# WKUP_j7aen_wkup_ctrl_mmr0_CFG0 register map
Vendor: Texas Instruments
Registers are 32-bit, read-write, reset 0x0 unless marked. A register's access mark holds for its fields unless they carry their own. Offsets are as the file gives them; [hi:lo] are bit positions; {n}, {i} and the like mark numbered series.

## WKUP_j7aen_wkup_ctrl_mmr0_CFG0 (part 3 of 3)
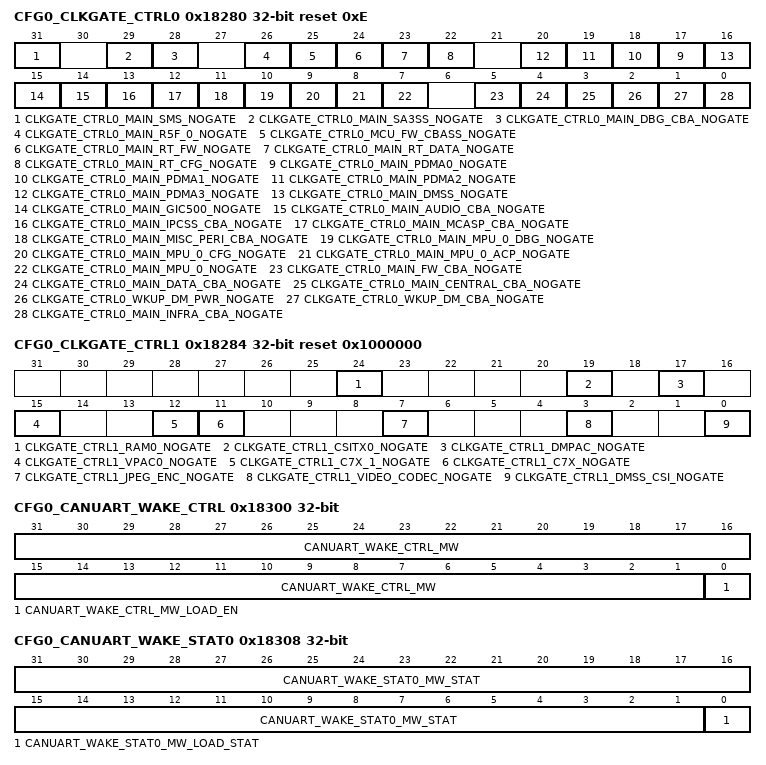
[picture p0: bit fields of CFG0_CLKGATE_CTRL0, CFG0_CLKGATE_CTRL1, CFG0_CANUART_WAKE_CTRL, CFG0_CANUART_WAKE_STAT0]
0x18280 CFG0_CLKGATE_CTRL0 reset 0xE
  [31] CLKGATE_CTRL0_MAIN_SMS_NOGATE — MAIN domain SMS auto clock gate on idle deactivate. Field values (others are reserved): 1'b0 - ACTIVE 1'b1 - INACTIVE
  [29] CLKGATE_CTRL0_MAIN_SA3SS_NOGATE — MAIN domain SA3SS auto clock gate on idle deactivate. Field values (others are reserved): 1'b0 - ACTIVE 1'b1 - INACTIVE
  [28] CLKGATE_CTRL0_MAIN_DBG_CBA_NOGATE — MAIN domain Debug CBASS auto clock gate on idle deactivate. Field values (others are reserved): 1'b0 - ACTIVE 1'b1 - INACTIVE
  [26] CLKGATE_CTRL0_MAIN_R5F_0_NOGATE — MAIN domain R5FSS auto clock gate on idle deactivate Field values (others are reserved): 1'b0 - ACTIVE 1'b1 - INACTIVE
  [25] CLKGATE_CTRL0_MCU_FW_CBASS_NOGATE — MCU domain FW CBASS auto clock gate on idle deactivate Field values (others are reserved): 1'b0 - ACTIVE 1'b1 - INACTIVE
  [24] CLKGATE_CTRL0_MAIN_RT_FW_NOGATE — MAIN domain RT FW CBASS auto clock gate on idle deactivate Field values (others are reserved): 1'b0 - ACTIVE 1'b1 - INACTIVE
  [23] CLKGATE_CTRL0_MAIN_RT_DATA_NOGATE — MAIN domain RT DATA CBASS auto clock gate on idle deactivate Field values (others are reserved): 1'b0 - ACTIVE 1'b1 - INACTIVE
  [22] CLKGATE_CTRL0_MAIN_RT_CFG_NOGATE — MAIN domain RT CFG CBASS auto clock gate on idle deactivate Field values (others are reserved): 1'b0 - ACTIVE 1'b1 - INACTIVE
  [n+17] CLKGATE_CTRL0_MAIN_PDMA{n}_NOGATE (n=0..3) — MAIN domain PDMA{n} auto clock gate on idle deactivate. Field values (others are reserved): 1'b0 - ACTIVE 1'b1 - INACTIVE
  [16] CLKGATE_CTRL0_MAIN_DMSS_NOGATE — MAIN domain DMSS auto clock gate on idle deactivate. Field values (others are reserved): 1'b0 - ACTIVE 1'b1 - INACTIVE
  [15] CLKGATE_CTRL0_MAIN_GIC500_NOGATE — MAIN MPUSS0 GIC500 auto clock gate on idle deactivate. Field values (others are reserved): 1'b0 - ACTIVE 1'b1 - INACTIVE
  [14] CLKGATE_CTRL0_MAIN_AUDIO_CBA_NOGATE — MAIN domain Infrastructure bus (AUDIO) auto clock gate on idle deactivate. Field values (others are reserved): 1'b0 - ACTIVE 1'b1 - INACTIVE
  [13] CLKGATE_CTRL0_MAIN_IPCSS_CBA_NOGATE — MAIN domain Infrastructure CBASS auto clock gate on idle deactivate. Field values (others are reserved): 1'b0 - ACTIVE 1'b1 - INACTIVE
  [12] CLKGATE_CTRL0_MAIN_MCASP_CBA_NOGATE — MAIN domain Infrastructure bus (McASP) auto clock gate on idle deactivate. Field values (others are reserved): 1'b0 - ACTIVE 1'b1 - INACTIVE
  [11] CLKGATE_CTRL0_MAIN_MISC_PERI_CBA_NOGATE — MAIN domain Infrastructure bus (Misc Peripehal) auto clock gate on idle deactivate. Field values (others are reserved): 1'b0 - ACTIVE 1'b1 - INACTIVE
  [10] CLKGATE_CTRL0_MAIN_MPU_0_DBG_NOGATE — MAIN MPUSS0 Debug Port auto clock gate on idle deactivate. Field values (others are reserved): 1'b0 - ACTIVE 1'b1 - INACTIVE
  [9] CLKGATE_CTRL0_MAIN_MPU_0_CFG_NOGATE — MAIN MPUSS0 Configuration Port auto clock gate on idle deactivate. Field values (others are reserved): 1'b0 - ACTIVE 1'b1 - INACTIVE
  [8] CLKGATE_CTRL0_MAIN_MPU_0_ACP_NOGATE — MAIN MPUSS0 ACP auto clock gate on idle deactivate. Field values (others are reserved): 1'b0 - ACTIVE 1'b1 - INACTIVE
  [7] CLKGATE_CTRL0_MAIN_MPU_0_NOGATE — MAIN MPUSS0 auto clock gate on idle deactivate. Field values (others are reserved): 1'b0 - ACTIVE 1'b1 - INACTIVE
  [5] CLKGATE_CTRL0_MAIN_FW_CBA_NOGATE — MAIN domain data bus auto clock gate on idle deactivate. Field values (others are reserved): 1'b0 - ACTIVE 1'b1 - INACTIVE
  [4] CLKGATE_CTRL0_MAIN_DATA_CBA_NOGATE — MAIN domain data bus auto clock gate on idle deactivate. Field values (others are reserved): 1'b0 - ACTIVE 1'b1 - INACTIVE
  [3] CLKGATE_CTRL0_MAIN_CENTRAL_CBA_NOGATE — WKUP domain Infrastructure ECC aggregator auto clock gate on idle deactivate. Field values (others are reserved): 1'b0 - ACTIVE 1'b1 - INACTIVE
  [2] CLKGATE_CTRL0_WKUP_DM_PWR_NOGATE — WKUP domain Device Manager auto clock gate on idle deactivate. Field values (others are reserved): 1'b0 - ACTIVE 1'b1 - INACTIVE
  [1] CLKGATE_CTRL0_WKUP_DM_CBA_NOGATE — WKUP domain device manager CBA auto clock gate on idle deactivate. Field values (others are reserved): 1'b0 - ACTIVE 1'b1 - INACTIVE
  [0] CLKGATE_CTRL0_MAIN_INFRA_CBA_NOGATE — MAIN domain Infrastructure bus auto clock gate on idle deactivate. Field values (others are reserved): 1'b0 - ACTIVE 1'b1 - INACTIVE
0x18284 CFG0_CLKGATE_CTRL1 reset 0x1000000
  [24] CLKGATE_CTRL1_RAM0_NOGATE — MAIN SRAM auto clockgate on idle deactivate Field values (others are reserved): 1'b0 - ACTIVE 1'b1 - INACTIVE
  [19] CLKGATE_CTRL1_CSITX0_NOGATE — CSI-TX0 auto clock gate on idle deactivate. Field values (others are reserved): 1'b0 - ACTIVE 1'b1 - INACTIVE
  [17] CLKGATE_CTRL1_DMPAC_NOGATE — DMPAC auto clock gate on idle deactivate. Field values (others are reserved): 1'b0 - ACTIVE 1'b1 - INACTIVE
  [15] CLKGATE_CTRL1_VPAC0_NOGATE — VPAC0 auto clock gate on idle deactivate. Field values (others are reserved): 1'b0 - ACTIVE 1'b1 - INACTIVE
  [12] CLKGATE_CTRL1_C7X_1_NOGATE — C7x_1 auto clock gate on idle deactivate. Field values (others are reserved): 1'b0 - ACTIVE 1'b1 - INACTIVE
  [11] CLKGATE_CTRL1_C7X_NOGATE — C7x auto clock gate on idle deactivate. Field values (others are reserved): 1'b0 - ACTIVE 1'b1 - INACTIVE
  [7] CLKGATE_CTRL1_JPEG_ENC_NOGATE — JPEG Encoder auto clock gate on idle deactivate. Field values (others are reserved): 1'b0 - ACTIVE 1'b1 - INACTIVE
  [3] CLKGATE_CTRL1_VIDEO_CODEC_NOGATE — VIDEO CODEC auto clock gate on idle deactivate. Field values (others are reserved): 1'b0 - ACTIVE 1'b1 - INACTIVE
  [0] CLKGATE_CTRL1_DMSS_CSI_NOGATE — DMSS_CSI auto clock gate on idle deactivate. Field values (others are reserved): 1'b0 - ACTIVE 1'b1 - INACTIVE
0x18300 CFG0_CANUART_WAKE_CTRL
  [31:1] CANUART_WAKE_CTRL_MW — CANUART IO magic word. The lower 23 bits determine if the device enters CANUART IO isolation when mw_load_en is set. If the lower 23 bits match the ACTIVATE value (0x5AAAAA), then CANUART IO Isolation is entered, any other value will prevent entry. The upper 8 bits of this register are software defined and do not determine whether or not CANUART IO isolation is entered. Field values (others are reserved): 31'h005AAAAA - ACTIVATE 31'h00000000 - DEACTIVATE
  [0] CANUART_WAKE_CTRL_MW_LOAD_EN — Magic word load activate Setting this bit loads and locks the mw field for CANUART IO isolation. If the mw field matches ACTIVATE, CANUART IO Isolation is initiated. Field values (others are reserved): 1'b0 - UNLOCK 1'b1 - LOCK_AND_LOAD
0x18308 CFG0_CANUART_WAKE_STAT0 ro
  [31:1] CANUART_WAKE_STAT0_MW_STAT — CANUART magic word status Indicates the latched value of the mw field.
  [0] CANUART_WAKE_STAT0_MW_LOAD_STAT — Magic word load status. Indicates the latched value of the mw_load_en bit
0x1830C CFG0_CANUART_WAKE_STAT1 ro
  [0] CANUART_WAKE_STAT1_CANUART_IO_MODE — Indicates if CANUART IO wakeup mode is activated. Field values (others are reserved): 1'b0 - INACTIVE 1'b1 - ACTIVATED
0x18310 CFG0_CANUART_WAKE_OFF_MODE
  [31:0] CANUART_WAKE_OFF_MODE_MW — magic word
0x18318 CFG0_CANUART_WAKE_OFF_MODE_STAT ro
  [31:0] CANUART_WAKE_OFF_MODE_STAT_MW — returned magic word
0x18320 CFG0_CANUART_WAKE_RESUME_KEY
  [31:0] KEYVAL — key value
0x18340 CFG0_CANUART_WAKE_RESUME_KEY_STAT ro
  [31:0] KEYVAL — returned key value
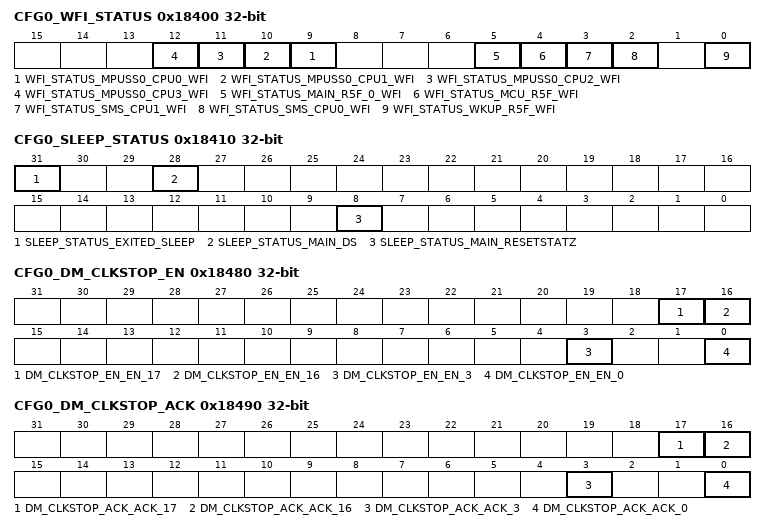
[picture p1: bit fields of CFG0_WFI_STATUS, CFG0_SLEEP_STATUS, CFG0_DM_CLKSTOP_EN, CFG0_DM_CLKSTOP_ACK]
0x18400 CFG0_WFI_STATUS ro
  [n+9] WFI_STATUS_MPUSS0_CPU{n}_WFI (n=0..3) — WFI status of MPUSS0 CPU{n} (only valid when CPU is out of reset) Field values (others are reserved): 1'b0 - UNKNOWN 1'b1 - WFI_ACTIVE
  [5] WFI_STATUS_MAIN_R5F_0_WFI — WFI status of MAIN Cortex R5F (only valid when CPU is out of reset) Field values (others are reserved): 1'b0 - UNKNOWN 1'b1 - WFI_ACTIVE
  [4] WFI_STATUS_MCU_R5F_WFI — WFI status of MCU Cortex R5F (only valid when CPU is out of reset) Field values (others are reserved): 1'b0 - UNKNOWN 1'b1 - WFI_ACTIVE
  [3] WFI_STATUS_SMS_CPU1_WFI — WFI status of SMS Cortex M4F1 (only valid when CPU is out of reset) Field values (others are reserved): 1'b0 - UNKNOWN 1'b1 - WFI_ACTIVE
  [2] WFI_STATUS_SMS_CPU0_WFI — WFI status of SMS Cortex M4F0 (only valid when CPU is out of reset) Field values (others are reserved): 1'b0 - UNKNOWN 1'b1 - WFI_ACTIVE
  [0] WFI_STATUS_WKUP_R5F_WFI — WFI status of Device Manager Cortex R5F (only valid when CPU is out of reset) Field values (others are reserved): 1'b0 - UNKNOWN 1'b1 - WFI_ACTIVE
0x18410 CFG0_SLEEP_STATUS access not given
  [31] SLEEP_STATUS_EXITED_SLEEP — Captures disable/gating of HFOSC. Allows DM to confirm, after the WFI instruction, to determine whether or not HFOSC clocks were actually gated (a pending event may cancel the sleep sequence early). Field values (others are reserved): 1'b0 - OTHER 1'b1 - SLEEP_EXIT (access R/W1TC)
  [28] SLEEP_STATUS_MAIN_DS — Captures DS_MAIN por_pdoff assertion, so that after deepsleep exit software can differentiate between a regular power on reset and a main power on reset due to deepsleep exit. Write 1 to Clear this bit. Field values (others are reserved): 1'b0 - OTHER 1'b1 - DS_EXIT (access R/W1TC)
  [8] SLEEP_STATUS_MAIN_RESETSTATZ ro — Reflects the status of the main domain reset (active low) Field values (others are reserved): 1'b0 - ASSERTED 1'b1 - DEASSERTED
0x18418 CFG0_DS_MAGIC_WORD
  [31:0] DS_MAGIC_WORD_DS_MAGIC_WORD — Magic Word Indicating State of Deep Sleep
0x18420 CFG0_DS_MAIN reset 0xF
  [3:0] DS_MAIN_POR_PDOFF — Signal Puts main SMS, DebugSS and MainIP Power Domains into Power Off state, and asserts Main Power On Reset. Field values (others are reserved): 4'b0110 - Off 4'b1111 - On
0x18440 CFG0_DS_DM_RESET reset 0xF
  [3:0] DS_DM_RESET_MASK — Signal used to mask main domain resets from Device Manager / Wakeup and MCU Ips Field values (others are reserved): 4'b0110 - Masked 4'b1111 - UnMasked
0x18460 CFG0_DS_USB0_RESET reset 0xF
  [3:0] DS_USB0_RESET_MASK — Signal used to block reset to the USBSS0 Field values (others are reserved): 4'b0110 - Masked 4'b1111 - UnMasked
0x18464 CFG0_DS_USB1_RESET reset 0xF
  [3:0] DS_USB1_RESET_MASK — Signal used to block reset to the USBSS1 Field values (others are reserved): 4'b0110 - Masked 4'b1111 - UnMasked
0x18480 CFG0_DM_CLKSTOP_EN
  [17] DM_CLKSTOP_EN_EN_17 — WKUP DMTIMER1 Participation in Clockstop Req Group Field values (others are reserved): 1'b0 - NOT_PARTICIPATING 1'b1 - PARTICIPATING
  [16] DM_CLKSTOP_EN_EN_16 — WKUP DMTIMER0 Participation in Clockstop Req Group Field values (others are reserved): 1'b0 - NOT_PARTICIPATING 1'b1 - PARTICIPATING
  [3] DM_CLKSTOP_EN_EN_3 — WKUP UART0 Participation in Clockstop Req Group Field values (others are reserved): 1'b0 - NOT_PARTICIPATING 1'b1 - PARTICIPATING
  [0] DM_CLKSTOP_EN_EN_0 — WKUP I2C0 Participation in Clockstop Req Group Field values (others are reserved): 1'b0 - NOT_PARTICIPATING 1'b1 - PARTICIPATING
0x18490 CFG0_DM_CLKSTOP_ACK ro
  [17] DM_CLKSTOP_ACK_ACK_17 — WKUP DMTIMER1 Clockstop Ack Status Field values (others are reserved): 1'b0 - NACK 1'b1 - ACK
  [16] DM_CLKSTOP_ACK_ACK_16 — WKUP DMTIMER0 Clockstop Ack Status Field values (others are reserved): 1'b0 - NACK 1'b1 - ACK
  [3] DM_CLKSTOP_ACK_ACK_3 — WKUP UART0 Clockstop Ack Status Field values (others are reserved): 1'b0 - NACK 1'b1 - ACK
  [0] DM_CLKSTOP_ACK_ACK_0 — WKUP I2C0 Clockstop Ack Status Field values (others are reserved): 1'b0 - NACK 1'b1 - ACK
0x184A0 CFG0_DM_GRP_CLKSTOP_REQ
  [0] DM_GRP_CLKSTOP_REQ_REQ — Controls Assertion of Clockstop Request to IPs participating in Clockstop Req Group Field values (others are reserved): 1'b0 - DEASSERT_REQ 1'b1 - ASSERT_REQ
0x184A4 CFG0_DM_GRP_CLKSTOP_ACK ro
  [0] DM_GRP_CLKSTOP_ACK_ACK — Status of IPs Participating in Clockstop Ack Group. If DM_CLKSTOP_EN is 0 (no IPs participating) this bit always reads 1. If one or more participating peripherals is returning NACK, this bit reads PENDING. Field values (others are reserved): 1'b0 - PENDING 1'b1 - ALL_ACK
0x18500 CFG0_DEVICE_TYPE ro
  [7:4] DEVICE_TYPE_SMS_DEV_TYPE — Type of device reported by SMS. Values not listed should be interpreted as BAD. Field values (others are reserved): 4b0101 - DT_TEST 4b1001 - DT_EMU 4b1010 - DT_HS 4b0011 - DT_GP
{0x19100+4i} CFG0_CLAIMREG_P6_R{i}_READONLY ro (i=0..10)
  [31:0] CLAIMREG_P6_R{i}_READONLY — Claim bits for Partition 6
0x1A040 CFG0_FW_CTRL_OUT0_PROXY
  [31:0] FW_CTRL_OUT0_FW_CTRL_OUT0_PROXY — Unused
0x1A044 CFG0_FW_CTRL_OUT0_SET_PROXY access not given reset not defined
0x1A048 CFG0_FW_CTRL_OUT0_CLR_PROXY access not given reset not defined
0x1A04C CFG0_FW_STS_IN0_PROXY access not given reset not defined
0x1A050 CFG0_FW_CTRL_OUT1_PROXY access not given reset not defined
0x1A054 CFG0_FW_CTRL_OUT1_SET_PROXY access not given reset not defined
0x1A058 CFG0_FW_CTRL_OUT1_CLR_PROXY access not given reset not defined
0x1A05C CFG0_FW_STS_IN1_PROXY access not given reset not defined
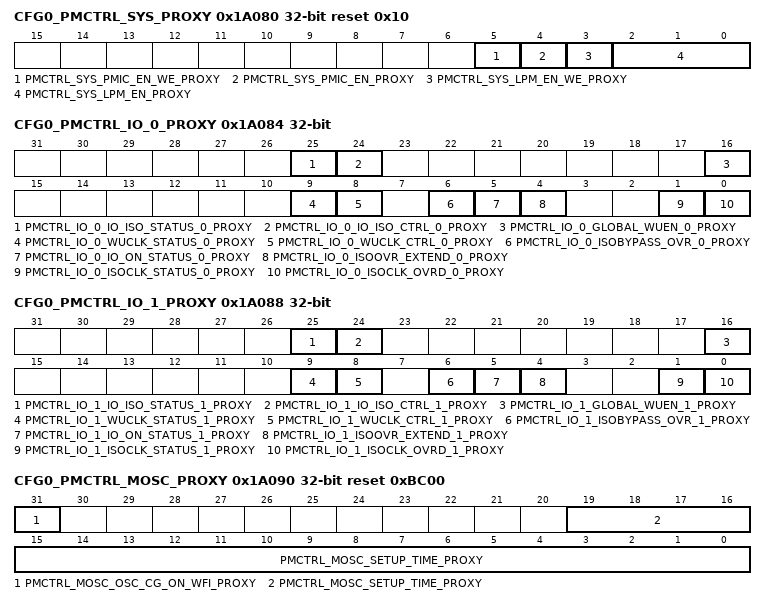
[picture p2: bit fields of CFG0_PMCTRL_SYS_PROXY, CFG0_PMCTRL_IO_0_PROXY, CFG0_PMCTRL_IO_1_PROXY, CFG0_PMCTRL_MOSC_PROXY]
0x1A080 CFG0_PMCTRL_SYS_PROXY reset 0x10
  [5] PMCTRL_SYS_PMIC_EN_WE_PROXY — Unused Field - Value is Don't Care
  [4] PMCTRL_SYS_PMIC_EN_PROXY — Controls state of PMIC_LPM_EN_OUT when LPM_EN[2:0] is 000
  [3] PMCTRL_SYS_LPM_EN_WE_PROXY — Unused Field - Value is Don't Care
  [2:0] PMCTRL_SYS_LPM_EN_PROXY — Controls whether PMIC_LPM_EN_OUT is driven by the pmic_en bit, or by deep sleep logic. Field values (others are reserved): 3'b000 - PMIC_LPM_EN_OUT controlled by pmic_en bit. 3'b101 - PMIC_LPM_EN_OUT controlled by DeepSleep Logic
0x1A084 CFG0_PMCTRL_IO_0_PROXY access per field
  [25] PMCTRL_IO_0_IO_ISO_STATUS_0_PROXY ro — IO ISO Status. Read 0: IO isolation not active. Read 1: IO isolation active. Reflects value of DM input port io_isoack coming back from IO pad ring.
  [24] PMCTRL_IO_0_IO_ISO_CTRL_0_PROXY rw — IO ISO control. Writing this bit to 1 will kick off IO isolation.
  [16] PMCTRL_IO_0_GLOBAL_WUEN_0_PROXY rw — Global IO wakeup activate. This is a gating condition to all individual IO WUEN coming from control module. Gating is done in the Spinner logic. 0:All individual IO WUEN are gated in the Spinner logic (override to 0). 1: All individual IO WUEN from control module are going to Ios. Map to DM input port io_globalwkupen
  [9] PMCTRL_IO_0_WUCLK_STATUS_0_PROXY ro — Reflects value of DM input port io_wuclkack coming back from IO pad ring.
  [8] PMCTRL_IO_0_WUCLK_CTRL_0_PROXY rw — Direct control on WUCLKIN signal to IO pad ring.0:WUCLKIN signal is driven to 0.IO wakeup daisy chain is functional as well as IO whose wakeup feature is activated. 1:WUCLKIN signal is driven to 1. IO wakeup daisy chain is reset and is latching current pad states and WUEN inputs.
  [6] PMCTRL_IO_0_ISOBYPASS_OVR_0_PROXY rw — This MMR bit drives directly DM output port io_isobypassundefined.
  [5] PMCTRL_IO_0_IO_ON_STATUS_0_PROXY ro — Gives the functional status of the IO ring. Read 0: Part or all of the Ios are not in the ON state that is are in isolation state. Read 1: All Ios are in the ON state. io_on_status = assign 1 if (io_iso == 0 & io_isoack==0 & io_iso_clk == 0 & io_isoclk_ack = 0 ) else 0;
  [4] PMCTRL_IO_0_ISOOVR_EXTEND_0_PROXY rw — This drives the SOC chain ISO-OVERRIDE global control. This bit drives directly the DM output port io_isoovrundefined. At the SOC level it is used to activate when 1 or gate-off when 0, the individual ISOOR for each IO. This operates as a global activate/disable for the individual IOs.Control for IO isolation extension. '0' IO isolation is not extended. Transition happens as soon as automatic restore is completed. '1' IO isolation is extended. The IOs whose ISOOVR bits have been individually set in their PADCFG MMRs will all get its IO isolation extended beyond the point when the initial IO daisy chain isolation is released.
  [1] PMCTRL_IO_0_ISOCLK_STATUS_0_PROXY ro — Reflects value of DM input port io_isoclkack coming back from IO pad ring.
  [0] PMCTRL_IO_0_ISOCLK_OVRD_0_PROXY rw — Override control on ISOCLKIN signal to IO pad ring. When not overridden this signal is controlled by hardware only. 0 ISOCLKIN signal is not override. 1 ISOCLKIN signal is overridden to active value ('1').
0x1A088 CFG0_PMCTRL_IO_1_PROXY access per field
  [25] PMCTRL_IO_1_IO_ISO_STATUS_1_PROXY ro — IO ISO Status. Read 0: IO isolation not active. Read 1: IO isolation active. Reflects value of DM input port io_isoack coming back from IO pad ring.
  [24] PMCTRL_IO_1_IO_ISO_CTRL_1_PROXY rw — IO ISO control. Writing this bit to 1 will kick off IO isolation.
  [16] PMCTRL_IO_1_GLOBAL_WUEN_1_PROXY rw — Global IO wakeup activate. This is a gating condition to all individual IO WUEN coming from control module. Gating is done in the Spinner logic. 0:All individual IO WUEN are gated in the Spinner logic (override to 0). 1: All individual IO WUEN from control module are going to Ios. Map to DM input port io_globalwkupen
  [9] PMCTRL_IO_1_WUCLK_STATUS_1_PROXY ro — Reflects value of DM input port io_wuclkack coming back from IO pad ring.
  [8] PMCTRL_IO_1_WUCLK_CTRL_1_PROXY rw — Direct control on WUCLKIN signal to IO pad ring.0:WUCLKIN signal is driven to 0.IO wakeup daisy chain is functional as well as IO whose wakeup feature is activated. 1:WUCLKIN signal is driven to 1. IO wakeup daisy chain is reset and is latching current pad states and WUEN inputs.
  [6] PMCTRL_IO_1_ISOBYPASS_OVR_1_PROXY rw — This MMR bit drives directly DM output port io_isobypassundefined.
  [5] PMCTRL_IO_1_IO_ON_STATUS_1_PROXY ro — Gives the functional status of the IO ring. Read 0: Part or all of the Ios are not in the ON state that is are in isolation state. Read 1: All Ios are in the ON state. io_on_status = assign 1 if (io_iso == 0 & io_isoack==0 & io_iso_clk == 0 & io_isoclk_ack = 0 ) else 0;
  [4] PMCTRL_IO_1_ISOOVR_EXTEND_1_PROXY rw — This drives the SOC chain ISO-OVERRIDE global control. This bit drives directly the DM output port io_isoovrundefined. At the SOC level it is used to activate when 1 or gate-off when 0, the individual ISOOR for each IO. This operates as a global activate/disable for the individual IOs.Control for IO isolation extension. '0' IO isolation is not extended. Transition happens as soon as automatic restore is completed. '1' IO isolation is extended. The IOs whose ISOOVR bits have been individually set in their PADCFG MMRs will all get its IO isolation extended beyond the point when the initial IO daisy chain isolation is released.
  [1] PMCTRL_IO_1_ISOCLK_STATUS_1_PROXY ro — Reflects value of DM input port io_isoclkack coming back from IO pad ring.
  [0] PMCTRL_IO_1_ISOCLK_OVRD_1_PROXY rw — Override control on ISOCLKIN signal to IO pad ring. When not overridden this signal is controlled by hardware only. 0 ISOCLKIN signal is not override. 1 ISOCLKIN signal is overridden to active value ('1').
0x1A090 CFG0_PMCTRL_MOSC_PROXY reset 0xBC00
  [31] PMCTRL_MOSC_OSC_CG_ON_WFI_PROXY — To clock gate the main HFOSC, DM sets this bit then enters the WFI state at which time the HFOSC will be gated. Field values (others are reserved): 1'b0 - INACTIVE 1'b1 - ACTIVE
  [19:0] PMCTRL_MOSC_SETUP_TIME_PROXY — Number of HFOSC clock cycles before HFOSC clock is ungated to the SOC (allows the HFOSC time to stabilize after starting up, before the SOC is clocked).
0x1A098 CFG0_PM_MISC_STATUS_PROXY ro
  [1:0] PM_MISC_STATUS_OSC_CG_STAT_PROXY — HFOSC Clock Gating State Field values (others are reserved): 2'b00 - HFOSC_OFF 2'b01 - HFOSC_OFF2ON (transition state) 2'b10 - HFOSC_ON2OFF (transition state) 2'b11 - HFOSC_ON
0x1A09C CFG0_PMCTRL_IO_GLB_PROXY
  [1:0] PMCTRL_IO_GLB_DSEN_QUALIFIED_PROXY — Bit 0 puts WKUP Domain IOs in Deepsleep. Bit 1 Puts Main Domain IOs in Deepsleep. Field values (others are reserved): 2'b00 - IO_ACTIVE_ALL 2'b01 - IO_DEEPSLEEP_WKUP 2'b10 - IO_DEEPSLEEP_MAIN 2'b11 - IO_DEEPSLEEP_MAIN_AND_WKUP
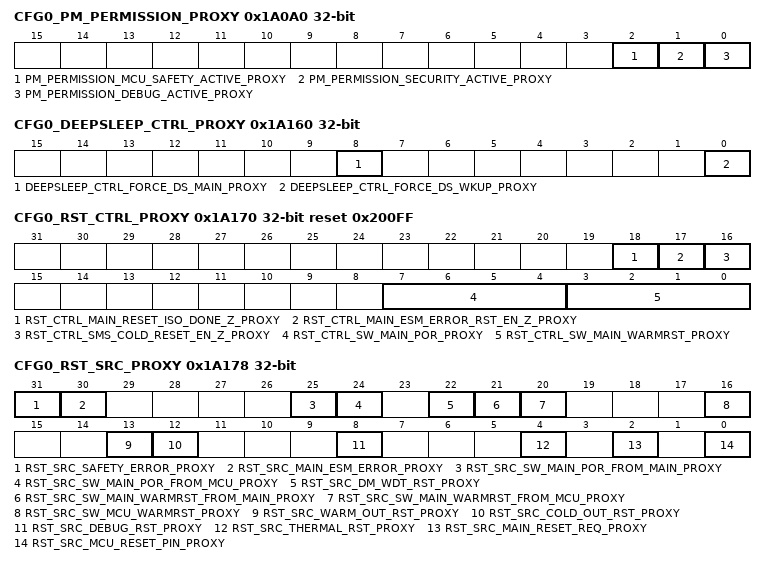
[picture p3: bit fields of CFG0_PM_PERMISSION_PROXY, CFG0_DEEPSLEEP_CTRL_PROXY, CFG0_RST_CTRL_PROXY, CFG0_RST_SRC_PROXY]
0x1A0A0 CFG0_PM_PERMISSION_PROXY ro
  [2] PM_PERMISSION_MCU_SAFETY_ACTIVE_PROXY — Read Only - Reads return a 1 when MCU RST_MAGIC_WORD is non-zero. When 1, indicates that the MCU is blocking reset and also deep sleep entry. Field values (others are reserved): 1'b0 - DS_ALLOW 1'b1 - DS_BLOCK
  [1] PM_PERMISSION_SECURITY_ACTIVE_PROXY — Read Only - Reads return the value of SMS security active. When 1, indicates that SMS is blocking deep sleep entry. Field values (others are reserved): 1'b0 - DS_ALLOW 1'b1 - DS_BLOCK
  [0] PM_PERMISSION_DEBUG_ACTIVE_PROXY — Read Only - Returns a 1 when Debug is blocking deep sleep entry. Field values (others are reserved): 1'b0 - DS_ALLOW 1'b1 - DS_BLOCK
0x1A160 CFG0_DEEPSLEEP_CTRL_PROXY
  [8] DEEPSLEEP_CTRL_FORCE_DS_MAIN_PROXY — Force all MAIN IOs into deepsleep mode when set Field values (others are reserved): 1'b0 - IO_ACTIVE 1'b1 - IO_DEEPSLEEP
  [0] DEEPSLEEP_CTRL_FORCE_DS_WKUP_PROXY — Force all WKUP IOs into deepsleep mode when set Field values (others are reserved): 1'b0 - IO_ACTIVE 1'b1 - IO_DEEPSLEEP
0x1A170 CFG0_RST_CTRL_PROXY reset 0x200FF
  [18] RST_CTRL_MAIN_RESET_ISO_DONE_Z_PROXY — Blocks Main Domain Warm Reset. Field values (others are reserved): 1'b0 - PROPOGATE 1'b1 - BLOCK
  [17] RST_CTRL_MAIN_ESM_ERROR_RST_EN_Z_PROXY — Block Reset of Main by ESM Field values (others are reserved): 1'b0 - PROPOGATE 1'b1 - BLOCK
  [16] RST_CTRL_SMS_COLD_RESET_EN_Z_PROXY — Block Reset of Main by SMS Field values (others are reserved): 1'b0 - PROPOGATE 1'b1 - BLOCK
  [7:4] RST_CTRL_SW_MAIN_POR_PROXY — Causes MAIN Domain Power On Reset. This is a fault tolerant bitfield. Automatically resets to 4'b1111 after write. Field values (others are reserved): 4'b0110 - FORCE_RESET 4'b1111 - INACTIVE
  [3:0] RST_CTRL_SW_MAIN_WARMRST_PROXY — Causes MAIN Domain Warm Reset. This is a fault tolerant bitfield. Automatically resets to 4'b1111 after write. Field values (others are reserved): 4'b0110 - FORCE_RESET 4'b1111 - INACTIVE
0x1A174 CFG0_RST_STAT_PROXY ro
  [0] RST_STAT_MCU_RESET_ISO_DONE_Z_PROXY — Indicates MCU Domain is in Reset Isolation When Active (Low) Field values (others are reserved): 1'b0 - ISOLATION 1'b1 - PASS_THROUGH
0x1A178 CFG0_RST_SRC_PROXY ro
  [31] RST_SRC_SAFETY_ERROR_PROXY — Reset Caused by MCU ESM Error. Field values (others are reserved): 1'b0 - UNKNOWN 1'b1 - DETECTED
  [30] RST_SRC_MAIN_ESM_ERROR_PROXY — Reset Caused by Main ESM Error. Field values (others are reserved): 1'b0 - UNKNOWN 1'b1 - DETECTED
  [25] RST_SRC_SW_MAIN_POR_FROM_MAIN_PROXY — Software Main Power On Reset From CTRL_MMR0. Field values (others are reserved): 1'b0 - UNKNOWN 1'b1 - DETECTED
  [24] RST_SRC_SW_MAIN_POR_FROM_MCU_PROXY — Software Main Power On Reset From MCU_CTRL_MMR0. Field values (others are reserved): 1'b0 - UNKNOWN 1'b1 - DETECTED
  [22] RST_SRC_DM_WDT_RST_PROXY — Watchdog Initiated Reset. Field values (others are reserved): 1'b0 - UNKNOWN 1'b1 - DETECTED
  [21] RST_SRC_SW_MAIN_WARMRST_FROM_MAIN_PROXY — Software Main Warm Reset From CTRL_MMR0. Field values (others are reserved): 1'b0 - UNKNOWN 1'b1 - DETECTED
  [20] RST_SRC_SW_MAIN_WARMRST_FROM_MCU_PROXY — Software Main Warm Reset From MCU_CTRL_MMR0. Field values (others are reserved): 1'b0 - UNKNOWN 1'b1 - DETECTED
  [16] RST_SRC_SW_MCU_WARMRST_PROXY — Software Warm Reset. Field values (others are reserved): 1'b0 - UNKNOWN 1'b1 - DETECTED
  [13] RST_SRC_WARM_OUT_RST_PROXY — SMS Warm Reset. Field values (others are reserved): 1'b0 - UNKNOWN 1'b1 - DETECTED
  [12] RST_SRC_COLD_OUT_RST_PROXY — SMS Cold Reset. Field values (others are reserved): 1'b0 - UNKNOWN 1'b1 - DETECTED
  [8] RST_SRC_DEBUG_RST_PROXY — Debug Subsystem Initiated Reset. Field values (others are reserved): 1'b0 - UNKNOWN 1'b1 - DETECTED
  [4] RST_SRC_THERMAL_RST_PROXY — Thermal Reset. Field values (others are reserved): 1'b0 - UNKNOWN 1'b1 - DETECTED
  [2] RST_SRC_MAIN_RESET_REQ_PROXY — Main Reset Pin. Field values (others are reserved): 1'b0 - UNKNOWN 1'b1 - DETECTED
  [0] RST_SRC_MCU_RESET_PIN_PROXY — Rest Caused by MCU Reset Pin. Field values (others are reserved): 1'b0 - UNKNOWN 1'b1 - DETECTED
0x1A17C CFG0_RST_MAGIC_WORD_PROXY ro
  [31:0] RST_MAGIC_WORD_MCU_MAGIC_WORD_PROXY — Magic Word Indicating Status of MCU Subsystem Boot
0x1A180 CFG0_WKUP0_EN_PROXY
  [31:0] WKUP0_EN_WKUPEN_PROXY — Activates Wakeup from on-chip sources. In addition to values listed, any OR combination of the values is also valid. Field values (others are reserved): 32'h00000001 - WKUP_I2C0 32'h00000002 - WKUP_USART0 32'h00000004 - MCU_GPIO0 32'h00000008 - DEBUG undefined - undefined 32'h00000020 - WKUP_TIMER0 32'h00000040 - WKUP_TIMER1 32'h00000080 - WKUP_RTC 32'h00000100 - MAIN_RESET_REQz 32'h00000200 - USB0_IN_BAND 32'h00000400 - USB1_IN_BAND 32'h00010000 - MAIN_IO_DAISY_CHAIN 32'h00020000 - MCU_IO_DAISY_CHAIN 32'h00040000 - CANUART_IO_DAISY_CHAIN
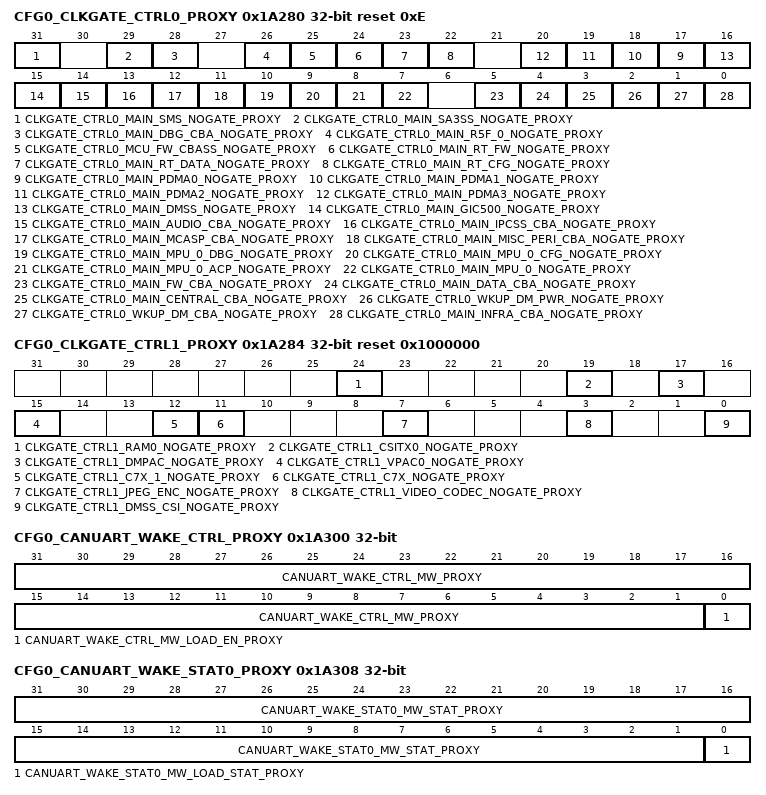
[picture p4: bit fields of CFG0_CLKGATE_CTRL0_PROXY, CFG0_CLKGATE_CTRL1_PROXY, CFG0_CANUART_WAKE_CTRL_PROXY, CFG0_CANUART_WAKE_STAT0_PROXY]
0x1A280 CFG0_CLKGATE_CTRL0_PROXY reset 0xE
  [31] CLKGATE_CTRL0_MAIN_SMS_NOGATE_PROXY — MAIN domain SMS auto clock gate on idle deactivate. Field values (others are reserved): 1'b0 - ACTIVE 1'b1 - INACTIVE
  [29] CLKGATE_CTRL0_MAIN_SA3SS_NOGATE_PROXY — MAIN domain SA3SS auto clock gate on idle deactivate. Field values (others are reserved): 1'b0 - ACTIVE 1'b1 - INACTIVE
  [28] CLKGATE_CTRL0_MAIN_DBG_CBA_NOGATE_PROXY — MAIN domain Debug CBASS auto clock gate on idle deactivate. Field values (others are reserved): 1'b0 - ACTIVE 1'b1 - INACTIVE
  [26] CLKGATE_CTRL0_MAIN_R5F_0_NOGATE_PROXY — MAIN domain R5FSS auto clock gate on idle deactivate Field values (others are reserved): 1'b0 - ACTIVE 1'b1 - INACTIVE
  [25] CLKGATE_CTRL0_MCU_FW_CBASS_NOGATE_PROXY — MCU domain FW CBASS auto clock gate on idle deactivate Field values (others are reserved): 1'b0 - ACTIVE 1'b1 - INACTIVE
  [24] CLKGATE_CTRL0_MAIN_RT_FW_NOGATE_PROXY — MAIN domain RT FW CBASS auto clock gate on idle deactivate Field values (others are reserved): 1'b0 - ACTIVE 1'b1 - INACTIVE
  [23] CLKGATE_CTRL0_MAIN_RT_DATA_NOGATE_PROXY — MAIN domain RT DATA CBASS auto clock gate on idle deactivate Field values (others are reserved): 1'b0 - ACTIVE 1'b1 - INACTIVE
  [22] CLKGATE_CTRL0_MAIN_RT_CFG_NOGATE_PROXY — MAIN domain RT CFG CBASS auto clock gate on idle deactivate Field values (others are reserved): 1'b0 - ACTIVE 1'b1 - INACTIVE
  [n+17] CLKGATE_CTRL0_MAIN_PDMA{n}_NOGATE_PROXY (n=0..3) — MAIN domain PDMA{n} auto clock gate on idle deactivate. Field values (others are reserved): 1'b0 - ACTIVE 1'b1 - INACTIVE
  [16] CLKGATE_CTRL0_MAIN_DMSS_NOGATE_PROXY — MAIN domain DMSS auto clock gate on idle deactivate. Field values (others are reserved): 1'b0 - ACTIVE 1'b1 - INACTIVE
  [15] CLKGATE_CTRL0_MAIN_GIC500_NOGATE_PROXY — MAIN MPUSS0 GIC500 auto clock gate on idle deactivate. Field values (others are reserved): 1'b0 - ACTIVE 1'b1 - INACTIVE
  [14] CLKGATE_CTRL0_MAIN_AUDIO_CBA_NOGATE_PROXY — MAIN domain Infrastructure bus (AUDIO) auto clock gate on idle deactivate. Field values (others are reserved): 1'b0 - ACTIVE 1'b1 - INACTIVE
  [13] CLKGATE_CTRL0_MAIN_IPCSS_CBA_NOGATE_PROXY — MAIN domain Infrastructure CBASS auto clock gate on idle deactivate. Field values (others are reserved): 1'b0 - ACTIVE 1'b1 - INACTIVE
  [12] CLKGATE_CTRL0_MAIN_MCASP_CBA_NOGATE_PROXY — MAIN domain Infrastructure bus (McASP) auto clock gate on idle deactivate. Field values (others are reserved): 1'b0 - ACTIVE 1'b1 - INACTIVE
  [11] CLKGATE_CTRL0_MAIN_MISC_PERI_CBA_NOGATE_PROXY — MAIN domain Infrastructure bus (Misc Peripehal) auto clock gate on idle deactivate. Field values (others are reserved): 1'b0 - ACTIVE 1'b1 - INACTIVE
  [10] CLKGATE_CTRL0_MAIN_MPU_0_DBG_NOGATE_PROXY — MAIN MPUSS0 Debug Port auto clock gate on idle deactivate. Field values (others are reserved): 1'b0 - ACTIVE 1'b1 - INACTIVE
  [9] CLKGATE_CTRL0_MAIN_MPU_0_CFG_NOGATE_PROXY — MAIN MPUSS0 Configuration Port auto clock gate on idle deactivate. Field values (others are reserved): 1'b0 - ACTIVE 1'b1 - INACTIVE
  [8] CLKGATE_CTRL0_MAIN_MPU_0_ACP_NOGATE_PROXY — MAIN MPUSS0 ACP auto clock gate on idle deactivate. Field values (others are reserved): 1'b0 - ACTIVE 1'b1 - INACTIVE
  [7] CLKGATE_CTRL0_MAIN_MPU_0_NOGATE_PROXY — MAIN MPUSS0 auto clock gate on idle deactivate. Field values (others are reserved): 1'b0 - ACTIVE 1'b1 - INACTIVE
  [5] CLKGATE_CTRL0_MAIN_FW_CBA_NOGATE_PROXY — MAIN domain data bus auto clock gate on idle deactivate. Field values (others are reserved): 1'b0 - ACTIVE 1'b1 - INACTIVE
  [4] CLKGATE_CTRL0_MAIN_DATA_CBA_NOGATE_PROXY — MAIN domain data bus auto clock gate on idle deactivate. Field values (others are reserved): 1'b0 - ACTIVE 1'b1 - INACTIVE
  [3] CLKGATE_CTRL0_MAIN_CENTRAL_CBA_NOGATE_PROXY — WKUP domain Infrastructure ECC aggregator auto clock gate on idle deactivate. Field values (others are reserved): 1'b0 - ACTIVE 1'b1 - INACTIVE
  [2] CLKGATE_CTRL0_WKUP_DM_PWR_NOGATE_PROXY — WKUP domain Device Manager auto clock gate on idle deactivate. Field values (others are reserved): 1'b0 - ACTIVE 1'b1 - INACTIVE
  [1] CLKGATE_CTRL0_WKUP_DM_CBA_NOGATE_PROXY — WKUP domain device manager CBA auto clock gate on idle deactivate. Field values (others are reserved): 1'b0 - ACTIVE 1'b1 - INACTIVE
  [0] CLKGATE_CTRL0_MAIN_INFRA_CBA_NOGATE_PROXY — MAIN domain Infrastructure bus auto clock gate on idle deactivate. Field values (others are reserved): 1'b0 - ACTIVE 1'b1 - INACTIVE
0x1A284 CFG0_CLKGATE_CTRL1_PROXY reset 0x1000000
  [24] CLKGATE_CTRL1_RAM0_NOGATE_PROXY — MAIN SRAM auto clockgate on idle deactivate Field values (others are reserved): 1'b0 - ACTIVE 1'b1 - INACTIVE
  [19] CLKGATE_CTRL1_CSITX0_NOGATE_PROXY — CSI-TX0 auto clock gate on idle deactivate. Field values (others are reserved): 1'b0 - ACTIVE 1'b1 - INACTIVE
  [17] CLKGATE_CTRL1_DMPAC_NOGATE_PROXY — DMPAC auto clock gate on idle deactivate. Field values (others are reserved): 1'b0 - ACTIVE 1'b1 - INACTIVE
  [15] CLKGATE_CTRL1_VPAC0_NOGATE_PROXY — VPAC0 auto clock gate on idle deactivate. Field values (others are reserved): 1'b0 - ACTIVE 1'b1 - INACTIVE
  [12] CLKGATE_CTRL1_C7X_1_NOGATE_PROXY — C7x_1 auto clock gate on idle deactivate. Field values (others are reserved): 1'b0 - ACTIVE 1'b1 - INACTIVE
  [11] CLKGATE_CTRL1_C7X_NOGATE_PROXY — C7x auto clock gate on idle deactivate. Field values (others are reserved): 1'b0 - ACTIVE 1'b1 - INACTIVE
  [7] CLKGATE_CTRL1_JPEG_ENC_NOGATE_PROXY — JPEG Encoder auto clock gate on idle deactivate. Field values (others are reserved): 1'b0 - ACTIVE 1'b1 - INACTIVE
  [3] CLKGATE_CTRL1_VIDEO_CODEC_NOGATE_PROXY — VIDEO CODEC auto clock gate on idle deactivate. Field values (others are reserved): 1'b0 - ACTIVE 1'b1 - INACTIVE
  [0] CLKGATE_CTRL1_DMSS_CSI_NOGATE_PROXY — DMSS_CSI auto clock gate on idle deactivate. Field values (others are reserved): 1'b0 - ACTIVE 1'b1 - INACTIVE
0x1A300 CFG0_CANUART_WAKE_CTRL_PROXY
  [31:1] CANUART_WAKE_CTRL_MW_PROXY — CANUART IO magic word. The lower 23 bits determine if the device enters CANUART IO isolation when mw_load_en is set. If the lower 23 bits match the ACTIVATE value (0x5AAAAA), then CANUART IO Isolation is entered, any other value will prevent entry. The upper 8 bits of this register are software defined and do not determine whether or not CANUART IO isolation is entered. Field values (others are reserved): 31'h005AAAAA - ACTIVATE 31'h00000000 - DEACTIVATE
  [0] CANUART_WAKE_CTRL_MW_LOAD_EN_PROXY — Magic word load activate Setting this bit loads and locks the mw field for CANUART IO isolation. If the mw field matches ACTIVATE, CANUART IO Isolation is initiated. Field values (others are reserved): 1'b0 - UNLOCK 1'b1 - LOCK_AND_LOAD
0x1A308 CFG0_CANUART_WAKE_STAT0_PROXY ro
  [31:1] CANUART_WAKE_STAT0_MW_STAT_PROXY — CANUART magic word status Indicates the latched value of the mw field.
  [0] CANUART_WAKE_STAT0_MW_LOAD_STAT_PROXY — Magic word load status. Indicates the latched value of the mw_load_en bit
0x1A30C CFG0_CANUART_WAKE_STAT1_PROXY ro
  [0] CANUART_WAKE_STAT1_CANUART_IO_MODE_PROXY — Indicates if CANUART IO wakeup mode is activated. Field values (others are reserved): 1'b0 - INACTIVE 1'b1 - ACTIVATED
0x1A310 CFG0_CANUART_WAKE_OFF_MODE_PROXY
  [31:0] CANUART_WAKE_OFF_MODE_MW_PROXY — magic word
0x1A318 CFG0_CANUART_WAKE_OFF_MODE_STAT_PROXY ro
  [31:0] CANUART_WAKE_OFF_MODE_STAT_MW_PROXY — returned magic word
0x1A320 CFG0_CANUART_WAKE_RESUME_KEY_PROXY
  [31:0] KEYVAL_PROXY — key value
0x1A340 CFG0_CANUART_WAKE_RESUME_KEY_STAT_PROXY ro
  [31:0] KEYVAL_PROXY — returned key value
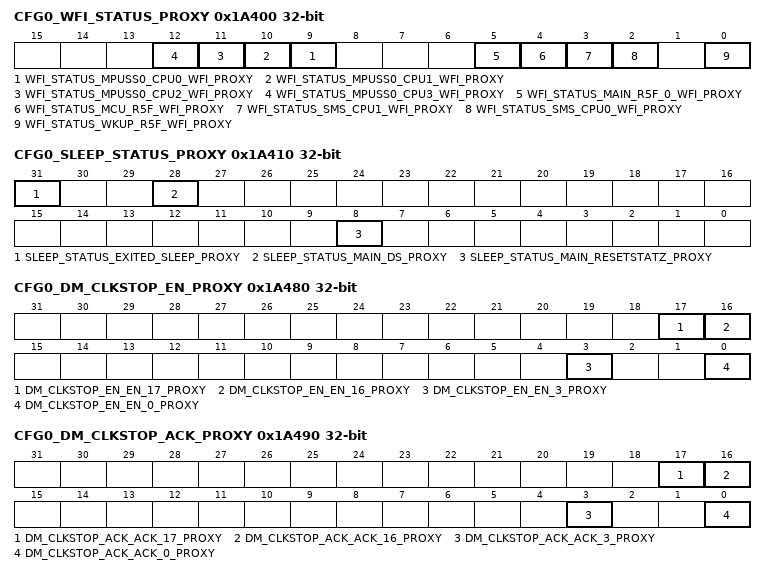
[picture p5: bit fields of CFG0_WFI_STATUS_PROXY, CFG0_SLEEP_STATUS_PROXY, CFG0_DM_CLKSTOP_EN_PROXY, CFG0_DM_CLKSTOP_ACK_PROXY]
0x1A400 CFG0_WFI_STATUS_PROXY ro
  [n+9] WFI_STATUS_MPUSS0_CPU{n}_WFI_PROXY (n=0..3) — WFI status of MPUSS0 CPU{n} (only valid when CPU is out of reset) Field values (others are reserved): 1'b0 - UNKNOWN 1'b1 - WFI_ACTIVE
  [5] WFI_STATUS_MAIN_R5F_0_WFI_PROXY — WFI status of MAIN Cortex R5F (only valid when CPU is out of reset) Field values (others are reserved): 1'b0 - UNKNOWN 1'b1 - WFI_ACTIVE
  [4] WFI_STATUS_MCU_R5F_WFI_PROXY — WFI status of MCU Cortex R5F (only valid when CPU is out of reset) Field values (others are reserved): 1'b0 - UNKNOWN 1'b1 - WFI_ACTIVE
  [3] WFI_STATUS_SMS_CPU1_WFI_PROXY — WFI status of SMS Cortex M4F1 (only valid when CPU is out of reset) Field values (others are reserved): 1'b0 - UNKNOWN 1'b1 - WFI_ACTIVE
  [2] WFI_STATUS_SMS_CPU0_WFI_PROXY — WFI status of SMS Cortex M4F0 (only valid when CPU is out of reset) Field values (others are reserved): 1'b0 - UNKNOWN 1'b1 - WFI_ACTIVE
  [0] WFI_STATUS_WKUP_R5F_WFI_PROXY — WFI status of Device Manager Cortex R5F (only valid when CPU is out of reset) Field values (others are reserved): 1'b0 - UNKNOWN 1'b1 - WFI_ACTIVE
0x1A410 CFG0_SLEEP_STATUS_PROXY access not given
  [31] SLEEP_STATUS_EXITED_SLEEP_PROXY — Captures disable/gating of HFOSC. Allows DM to confirm, after the WFI instruction, to determine whether or not HFOSC clocks were actually gated (a pending event may cancel the sleep sequence early). Field values (others are reserved): 1'b0 - OTHER 1'b1 - SLEEP_EXIT (access R/W1TC)
  [28] SLEEP_STATUS_MAIN_DS_PROXY — Captures DS_MAIN por_pdoff assertion, so that after deepsleep exit software can differentiate between a regular power on reset and a main power on reset due to deepsleep exit. Write 1 to Clear this bit. Field values (others are reserved): 1'b0 - OTHER 1'b1 - DS_EXIT (access R/W1TC)
  [8] SLEEP_STATUS_MAIN_RESETSTATZ_PROXY ro — Reflects the status of the main domain reset (active low) Field values (others are reserved): 1'b0 - ASSERTED 1'b1 - DEASSERTED
0x1A418 CFG0_DS_MAGIC_WORD_PROXY
  [31:0] DS_MAGIC_WORD_DS_MAGIC_WORD_PROXY — Magic Word Indicating State of Deep Sleep
0x1A420 CFG0_DS_MAIN_PROXY reset 0xF
  [3:0] DS_MAIN_POR_PDOFF_PROXY — Signal Puts main SMS, DebugSS and MainIP Power Domains into Power Off state, and asserts Main Power On Reset. Field values (others are reserved): 4'b0110 - Off 4'b1111 - On
0x1A440 CFG0_DS_DM_RESET_PROXY reset 0xF
  [3:0] DS_DM_RESET_MASK_PROXY — Signal used to mask main domain resets from Device Manager / Wakeup and MCU Ips Field values (others are reserved): 4'b0110 - Masked 4'b1111 - UnMasked
0x1A460 CFG0_DS_USB0_RESET_PROXY reset 0xF
  [3:0] DS_USB0_RESET_MASK_PROXY — Signal used to block reset to the USBSS0 Field values (others are reserved): 4'b0110 - Masked 4'b1111 - UnMasked
0x1A464 CFG0_DS_USB1_RESET_PROXY reset 0xF
  [3:0] DS_USB1_RESET_MASK_PROXY — Signal used to block reset to the USBSS1 Field values (others are reserved): 4'b0110 - Masked 4'b1111 - UnMasked
0x1A480 CFG0_DM_CLKSTOP_EN_PROXY
  [17] DM_CLKSTOP_EN_EN_17_PROXY — WKUP DMTIMER1 Participation in Clockstop Req Group Field values (others are reserved): 1'b0 - NOT_PARTICIPATING 1'b1 - PARTICIPATING
  [16] DM_CLKSTOP_EN_EN_16_PROXY — WKUP DMTIMER0 Participation in Clockstop Req Group Field values (others are reserved): 1'b0 - NOT_PARTICIPATING 1'b1 - PARTICIPATING
  [3] DM_CLKSTOP_EN_EN_3_PROXY — WKUP UART0 Participation in Clockstop Req Group Field values (others are reserved): 1'b0 - NOT_PARTICIPATING 1'b1 - PARTICIPATING
  [0] DM_CLKSTOP_EN_EN_0_PROXY — WKUP I2C0 Participation in Clockstop Req Group Field values (others are reserved): 1'b0 - NOT_PARTICIPATING 1'b1 - PARTICIPATING
0x1A490 CFG0_DM_CLKSTOP_ACK_PROXY ro
  [17] DM_CLKSTOP_ACK_ACK_17_PROXY — WKUP DMTIMER1 Clockstop Ack Status Field values (others are reserved): 1'b0 - NACK 1'b1 - ACK
  [16] DM_CLKSTOP_ACK_ACK_16_PROXY — WKUP DMTIMER0 Clockstop Ack Status Field values (others are reserved): 1'b0 - NACK 1'b1 - ACK
  [3] DM_CLKSTOP_ACK_ACK_3_PROXY — WKUP UART0 Clockstop Ack Status Field values (others are reserved): 1'b0 - NACK 1'b1 - ACK
  [0] DM_CLKSTOP_ACK_ACK_0_PROXY — WKUP I2C0 Clockstop Ack Status Field values (others are reserved): 1'b0 - NACK 1'b1 - ACK
0x1A4A0 CFG0_DM_GRP_CLKSTOP_REQ_PROXY
  [0] DM_GRP_CLKSTOP_REQ_REQ_PROXY — Controls Assertion of Clockstop Request to IPs participating in Clockstop Req Group Field values (others are reserved): 1'b0 - DEASSERT_REQ 1'b1 - ASSERT_REQ
0x1A4A4 CFG0_DM_GRP_CLKSTOP_ACK_PROXY ro
  [0] DM_GRP_CLKSTOP_ACK_ACK_PROXY — Status of IPs Participating in Clockstop Ack Group. If DM_CLKSTOP_EN is 0 (no IPs participating) this bit always reads 1. If one or more participating peripherals is returning NACK, this bit reads PENDING. Field values (others are reserved): 1'b0 - PENDING 1'b1 - ALL_ACK
0x1A500 CFG0_DEVICE_TYPE_PROXY ro
  [7:4] DEVICE_TYPE_SMS_DEV_TYPE_PROXY — Type of device reported by SMS. Values not listed should be interpreted as BAD. Field values (others are reserved): 4b0101 - DT_TEST 4b1001 - DT_EMU 4b1010 - DT_HS 4b0011 - DT_GP
{0x1B100+4i} CFG0_CLAIMREG_P6_R{i} (i=0..10)
  [31:0] CLAIMREG_P6_R{i} — Claim bits for Partition 6
0x1C100 CFG0_BACKUP_REG
  [31:0] BACKUP_DATA — Storage for Backup Data During Deep Sleep
{0x1D100+4i} CFG0_CLAIMREG_P7_R{i}_READONLY ro (i=0..2)
  [31:0] CLAIMREG_P7_R{i}_READONLY — Claim bits for Partition 7
0x1E100 CFG0_BACKUP_REG_PROXY
  [31:0] BACKUP_DATA_PROXY — Storage for Backup Data During Deep Sleep
{0x1F100+4i} CFG0_CLAIMREG_P7_R{i} (i=0..2)
  [31:0] CLAIMREG_P7_R{i} — Claim bits for Partition 7
